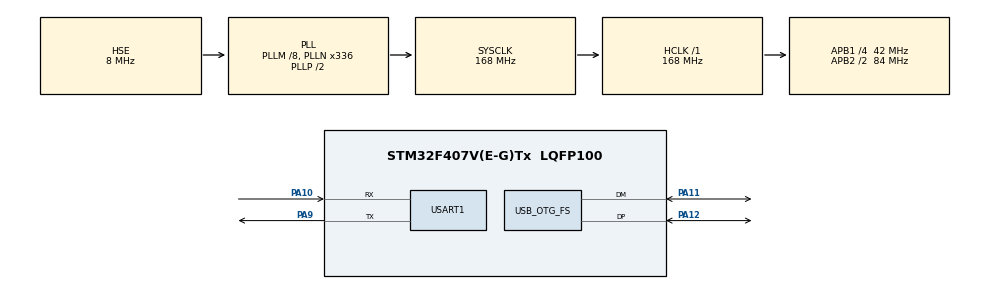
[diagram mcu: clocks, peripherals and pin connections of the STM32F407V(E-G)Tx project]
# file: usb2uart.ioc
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Mcu.Family=STM32F4
Mcu.Name=STM32F407V(E-G)Tx
Mcu.Package=LQFP100
NVIC.OTG_FS_IRQn=true\:0\:0\:false\:false\:true\:false\:true\:true
NVIC.PriorityGroup=NVIC_PRIORITYGROUP_4
NVIC.USART1_IRQn=true\:0\:0\:false\:false\:true\:true\:true\:true
PA10.Mode=Asynchronous
PA10.Signal=USART1_RX
PA11.Mode=Device_Only
PA11.Signal=USB_OTG_FS_DM
PA12.Mode=Device_Only
PA12.Signal=USB_OTG_FS_DP
PA9.Mode=Asynchronous
PA9.Signal=USART1_TX
PC14-OSC32_IN.Mode=LSE-External-Oscillator
PC14-OSC32_IN.Signal=RCC_OSC32_IN
PC15-OSC32_OUT.Mode=LSE-External-Oscillator
PC15-OSC32_OUT.Signal=RCC_OSC32_OUT
PH0-OSC_IN.Mode=HSE-External-Oscillator
PH0-OSC_IN.Signal=RCC_OSC_IN
PH1-OSC_OUT.Mode=HSE-External-Oscillator
PH1-OSC_OUT.Signal=RCC_OSC_OUT
ProjectManager.HeapSize=0x200
ProjectManager.StackSize=0x400
ProjectManager.TargetToolchain=Makefile
RCC.48MHZClocksFreq_Value=48000000
RCC.AHBFreq_Value=168000000
RCC.APB1CLKDivider=RCC_HCLK_DIV4
RCC.APB1Freq_Value=42000000
RCC.APB1TimFreq_Value=84000000
RCC.APB2CLKDivider=RCC_HCLK_DIV2
RCC.APB2Freq_Value=84000000
RCC.APB2TimFreq_Value=168000000
RCC.CortexFreq_Value=168000000
RCC.HCLKFreq_Value=168000000
RCC.HSE_VALUE=8000000
RCC.HSI_VALUE=16000000
RCC.PLLM=8
RCC.PLLN=336
RCC.PLLQ=7
RCC.SYSCLKFreq_VALUE=168000000
RCC.SYSCLKSource=RCC_SYSCLKSOURCE_PLLCLK
RCC.VCOOutputFreq_Value=336000000
USART1.VirtualMode=VM_ASYNC
USB_DEVICE.CLASS_NAME_FS=CDC
USB_DEVICE.USBD_DEBUG_LEVEL-CDC_FS=3
USB_DEVICE.VirtualMode-CDC_FS=Cdc
USB_DEVICE.VirtualModeFS=Cdc_FS
USB_OTG_FS.VirtualMode=Device_Only
VP_USB_DEVICE_VS_USB_DEVICE_CDC_FS.Mode=CDC_FS
board=custom

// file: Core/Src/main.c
/* USER CODE BEGIN Header */
/**
  ******************************************************************************
  * @file           : main.c
  * @brief          : Main program body
  ******************************************************************************
  * @attention
  *
  * Copyright (c) 2024 STMicroelectronics.
  * All rights reserved.
  *
  * This software is licensed under terms that can be found in the LICENSE file
  * in the root directory of this software component.
  * If no LICENSE file comes with this software, it is provided AS-IS.
  *
  ******************************************************************************
  */
/* USER CODE END Header */
#include "main.h"
#include "usb_device.h"
#include "usbd_cdc_if.h"

UART_HandleTypeDef huart1;

/* USER CODE BEGIN PV */
uint8_t Buffer1[128];
volatile uint8_t Tx1 = 0;
volatile uint8_t Rx1 = 0;
volatile uint8_t Empty1 = 1;

/* USER CODE END PV */

void SystemClock_Config(void);
static void MX_GPIO_Init(void);
static void MX_USART1_UART_Init(void);

/* USER CODE BEGIN 0 */
void HAL_UART_RxCpltCallback(UART_HandleTypeDef *huart)
{
  if (huart == &huart1) {
    if (++Rx1 == sizeof(Buffer1)) Rx1 = 0;
    Empty1 = 0;
    HAL_UART_Receive_IT(&huart1, &Buffer1[Rx1], 1);
  }
}

void USB_CDC_RxHandler(uint8_t* Buf, uint32_t Len)
{
    HAL_UART_Transmit(&huart1, Buf, Len, 1000);
}

/* USER CODE END 0 */

int main(void)
{

  /* MCU Configuration--------------------------------------------------------*/

  /* Reset of all peripherals, Initializes the Flash interface and the Systick. */
  HAL_Init();

  /* Configure the system clock */
  SystemClock_Config();

  /* Initialize all configured peripherals */
  MX_GPIO_Init();
  MX_USART1_UART_Init();
  MX_USB_DEVICE_Init();
  /* USER CODE BEGIN 2 */
  HAL_UART_Receive_IT(&huart1, &Buffer1[Rx1], 1);
  /* USER CODE END 2 */

  /* Infinite loop */
  /* USER CODE BEGIN WHILE */
  while (1)
  {
    uint8_t Rx;
    /* USER CODE END WHILE */
    if (!Empty1 && (Rx = Rx1) != Tx1) {
       uint8_t Tx = Rx > Tx1 ? Rx : sizeof(Buffer1);
       uint8_t Len = Tx - Tx1;
       if (CDC_Transmit_FS (&Buffer1[Tx1], Len) == USBD_OK) {
          Tx1 = Tx == sizeof(Buffer1) ? 0 : Tx;
       }
    }
  }
}

void SystemClock_Config(void)
{
  RCC_OscInitTypeDef RCC_OscInitStruct = {0};
  RCC_ClkInitTypeDef RCC_ClkInitStruct = {0};

  /** Configure the main internal regulator output voltage
  */
  __HAL_RCC_PWR_CLK_ENABLE();
  __HAL_PWR_VOLTAGESCALING_CONFIG(PWR_REGULATOR_VOLTAGE_SCALE1);

  /** Initializes the RCC Oscillators according to the specified parameters
  * in the RCC_OscInitTypeDef structure.
  */
  RCC_OscInitStruct.OscillatorType = RCC_OSCILLATORTYPE_HSE;
  RCC_OscInitStruct.HSEState = RCC_HSE_ON;
  RCC_OscInitStruct.PLL.PLLState = RCC_PLL_ON;
  RCC_OscInitStruct.PLL.PLLSource = RCC_PLLSOURCE_HSE;
  RCC_OscInitStruct.PLL.PLLM = 8;
  RCC_OscInitStruct.PLL.PLLN = 336;
  RCC_OscInitStruct.PLL.PLLP = RCC_PLLP_DIV2;
  RCC_OscInitStruct.PLL.PLLQ = 7;
  if (HAL_RCC_OscConfig(&RCC_OscInitStruct) != HAL_OK)
  {
    Error_Handler();
  }

  /** Initializes the CPU, AHB and APB buses clocks
  */
  RCC_ClkInitStruct.ClockType = RCC_CLOCKTYPE_HCLK|RCC_CLOCKTYPE_SYSCLK
                              |RCC_CLOCKTYPE_PCLK1|RCC_CLOCKTYPE_PCLK2;
  RCC_ClkInitStruct.SYSCLKSource = RCC_SYSCLKSOURCE_PLLCLK;
  RCC_ClkInitStruct.AHBCLKDivider = RCC_SYSCLK_DIV1;
  RCC_ClkInitStruct.APB1CLKDivider = RCC_HCLK_DIV4;
  RCC_ClkInitStruct.APB2CLKDivider = RCC_HCLK_DIV2;

  if (HAL_RCC_ClockConfig(&RCC_ClkInitStruct, FLASH_LATENCY_5) != HAL_OK)
  {
    Error_Handler();
  }
}

static void MX_USART1_UART_Init(void)
{

  huart1.Instance = USART1;
  huart1.Init.BaudRate = 115200;
  huart1.Init.WordLength = UART_WORDLENGTH_8B;
  huart1.Init.StopBits = UART_STOPBITS_1;
  huart1.Init.Parity = UART_PARITY_NONE;
  huart1.Init.Mode = UART_MODE_TX_RX;
  huart1.Init.HwFlowCtl = UART_HWCONTROL_NONE;
  huart1.Init.OverSampling = UART_OVERSAMPLING_16;
  if (HAL_UART_Init(&huart1) != HAL_OK)
  {
    Error_Handler();
  }

}

static void MX_GPIO_Init(void)
{

  /* GPIO Ports Clock Enable */
  __HAL_RCC_GPIOC_CLK_ENABLE();
  __HAL_RCC_GPIOH_CLK_ENABLE();
  __HAL_RCC_GPIOA_CLK_ENABLE();

}

void Error_Handler(void)
{
  __disable_irq();
  while (1)
  {
  }
}

void _init(){}
